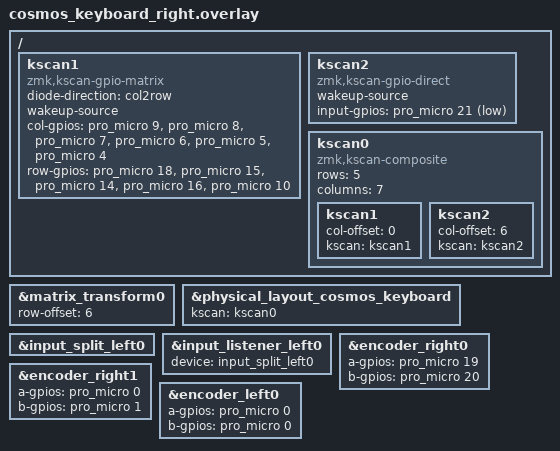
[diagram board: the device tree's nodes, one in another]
#include "cosmos_keyboard.dtsi"

/ {
    kscan1: kscan1 {
        compatible = "zmk,kscan-gpio-matrix";
                diode-direction = "col2row";
        wakeup-source;

        col-gpios
            = <&pro_micro 9 GPIO_ACTIVE_HIGH>
            , <&pro_micro 8 GPIO_ACTIVE_HIGH>
            , <&pro_micro 7 GPIO_ACTIVE_HIGH>
            , <&pro_micro 6 GPIO_ACTIVE_HIGH>
            , <&pro_micro 5 GPIO_ACTIVE_HIGH>
            , <&pro_micro 4 GPIO_ACTIVE_HIGH>
            ;

        row-gpios
            = <&pro_micro 18 (GPIO_ACTIVE_HIGH | GPIO_PULL_DOWN)>
            , <&pro_micro 15 (GPIO_ACTIVE_HIGH | GPIO_PULL_DOWN)>
            , <&pro_micro 14 (GPIO_ACTIVE_HIGH | GPIO_PULL_DOWN)>
            , <&pro_micro 16 (GPIO_ACTIVE_HIGH | GPIO_PULL_DOWN)>
            , <&pro_micro 10 (GPIO_ACTIVE_HIGH | GPIO_PULL_DOWN)>
            ;
    };
};

/ {
    kscan2: kscan2 {
        compatible = "zmk,kscan-gpio-direct";
        wakeup-source;

        input-gpios
            = <&pro_micro 21 (GPIO_ACTIVE_LOW | GPIO_PULL_UP)>
            ;
    };
};

/ {
    kscan0: kscan0 {
        compatible = "zmk,kscan-composite";
        rows = <5>;
        columns = <7>;

        kscan1 {
            col-offset = <0>;
            kscan = <&kscan1>;
        };
        kscan2 {
            col-offset = <6>;
            kscan = <&kscan2>;
        };
    };
};

&matrix_transform0 {
    row-offset = <6>;
};

&physical_layout_cosmos_keyboard {
    kscan = <&kscan0>;
};
// == Input devices ==
// Central half: hosts the listener for the left half's trackball. No `device`
// here - this is the receiving end, matched to the left's node by its `reg`.
&input_split_left0 {
    status = "okay";
};

&input_listener_left0 {
    status = "okay";
    device = <&input_split_left0>;
};

&encoder_right0 {
    a-gpios = <&pro_micro 19 (GPIO_ACTIVE_HIGH | GPIO_PULL_UP)>;
    b-gpios = <&pro_micro 20 (GPIO_ACTIVE_HIGH | GPIO_PULL_UP)>;
    status = "okay";
};
&encoder_right1 {
    a-gpios = <&pro_micro 0 (GPIO_ACTIVE_HIGH | GPIO_PULL_UP)>;
    b-gpios = <&pro_micro 1 (GPIO_ACTIVE_HIGH | GPIO_PULL_UP)>;
    status = "okay";
};

// Dummy pins for the other part's encoders, to satisfy devicetree. These nodes
// stay disabled, so nothing is compiled for them.
&encoder_left0 {
    a-gpios = <&pro_micro 0 (GPIO_ACTIVE_HIGH | GPIO_PULL_UP)>;
    b-gpios = <&pro_micro 0 (GPIO_ACTIVE_HIGH | GPIO_PULL_UP)>;
};
